AUTOSAR XML (schema 00050)
package /ARRoot/ApplicationDataType
  app type apdt_humidity: category=VALUE
  app type apdt_temp: category=VALUE
package /ARRoot/SwComponents/PortInterfaces
  client server interface csi_climate_control
    4 x operation:
      cso_turn_off_cooling
      cso_turn_off_heating
      cso_turn_on_cooling
      cso_turn_on_heating
  sender receiver interface sri_humidity: is-service=true
    data vdp_humidity: type=apdt_humidity
  sender receiver interface sri_temperature: is-service=true
    data vdp_temperature: type=apdt_temp
package /ARRoot/SwComponents/SwComponentTypes/AtomicSwComponentTypes
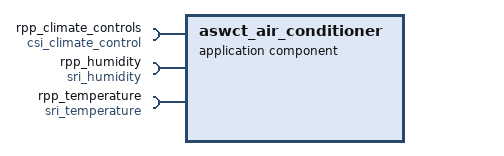
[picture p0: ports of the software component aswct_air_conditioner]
  application sw component type aswct_air_conditioner
    require port rpp_climate_controls: required-interface=csi_climate_control
    require port rpp_humidity: required-interface=sri_humidity
    require port rpp_temperature: required-interface=sri_temperature
    behavior swcib_air_conditioner
  application sw component type aswct_climate_controller
    provide port ppp_climate_controller: provided-interface=csi_climate_control
  application sw component type aswct_humidity_provider
    provide port ppp_humidity: provided-interface=sri_humidity
  application sw component type aswct_temperature_display
    require port rpp_temperature: required-interface=sri_temperature
  application sw component type aswct_temperature_provider
    provide port ppp_temperature: provided-interface=sri_temperature
package /ARRoot/SwComponents/SwComponentTypes/CompositionSwComponentTypes
  composition sw component type cswct_air_conditioner_root_sw
    4 x component:
      scp_air_conditioner: type=aswct_air_conditioner
      scp_climate_controller: type=aswct_climate_controller
      scp_indoor_sensors: type=cswct_indoor_sensors
      scp_temperature_display: type=aswct_temperature_display
    connect scp_climate_controller.ppp_climate_controller -> scp_air_conditioner.rpp_climate_controls
    connect scp_indoor_sensors.ppp_humidity -> scp_air_conditioner.rpp_humidity
    connect scp_indoor_sensors.ppp_temperature -> scp_air_conditioner.rpp_temperature
    connect scp_indoor_sensors.ppp_temperature -> scp_temperature_display.rpp_temperature
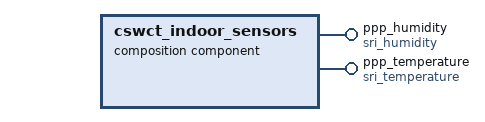
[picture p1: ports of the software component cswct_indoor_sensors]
  composition sw component type cswct_indoor_sensors
    provide port ppp_humidity: provided-interface=sri_humidity
    provide port ppp_temperature: provided-interface=sri_temperature
    component scp_humidity_provider: type=aswct_humidity_provider
    component scp_temperature_provider: type=aswct_temperature_provider
    delegate scp_humidity_provider.ppp_humidity <-> outer port cswct_indoor_sensors/ppp_humidity
    delegate scp_temperature_provider.ppp_temperature <-> outer port cswct_indoor_sensors/ppp_temperature
